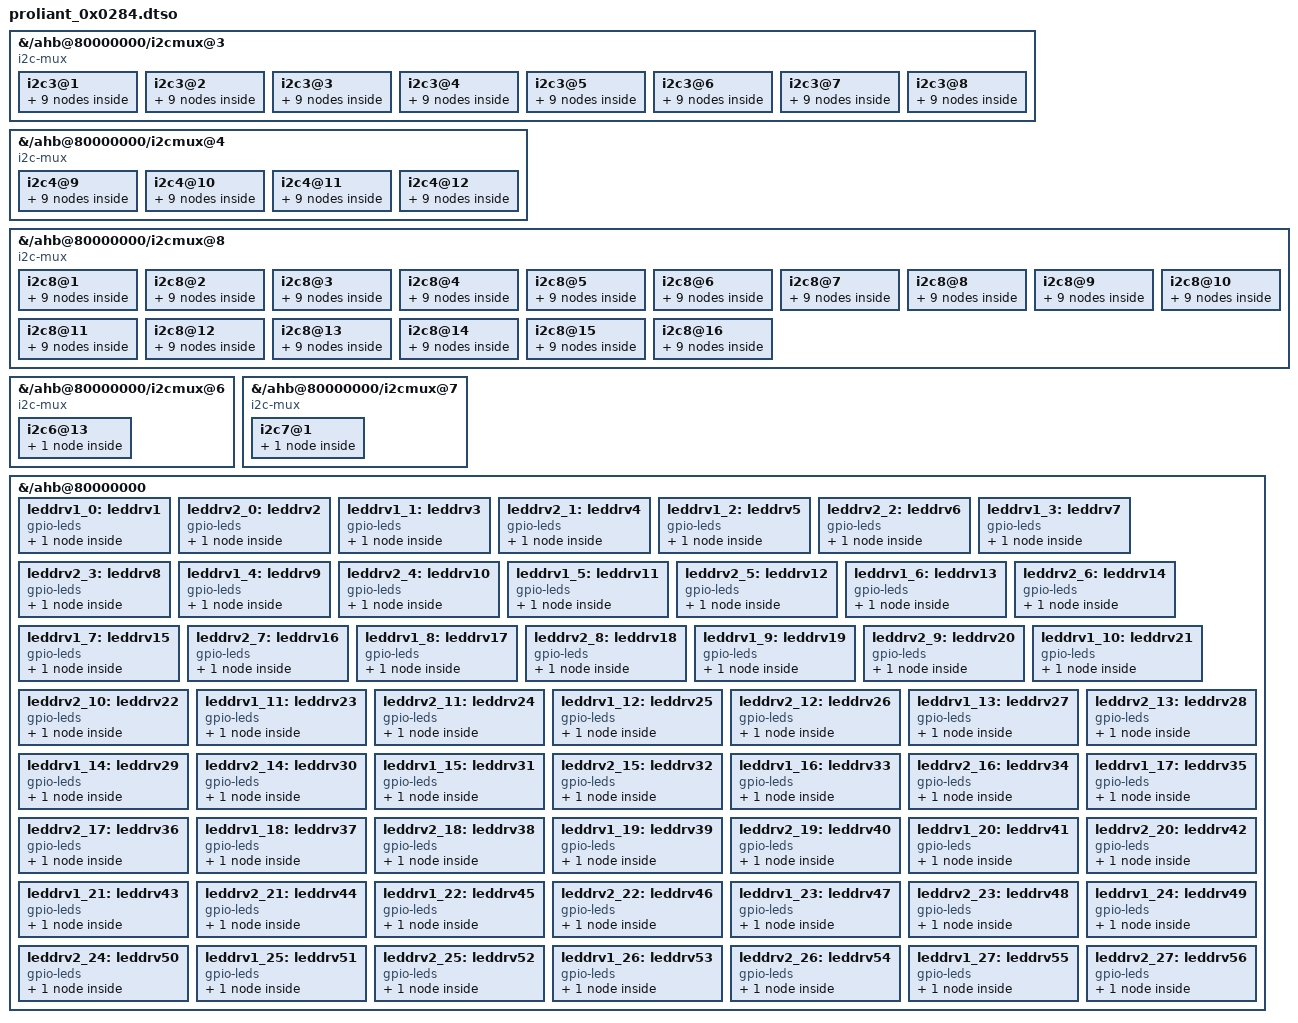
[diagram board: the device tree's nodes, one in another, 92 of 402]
/dts-v1/;
/plugin/;
/*
 * Device Tree Source Overlay for HPE ProLiant platform 0x0284
 * Auto-generated by platdef_parser.py from BIOS platdef data.
 *
 * i2cmux@N = platdef Engine N  |  sel value = i2cN@sel in child node
 *
 * i2cmux@3 (CPLD 0x87): 8 UBM channel(s), sel 1-8
 * i2cmux@4 (CPLD 0x88): 4 UBM channel(s), sel 9-12
 * i2cmux@8 (CPLD 0x8c): 16 UBM channel(s), sel 1-16
 * i2cmux@6: Power Supply 2 (psu2) sel=13 addr=0x5c
 * i2cmux@7: Power Supply 1 (psu1) sel=1 addr=0x5c
 */

/ {
	/*
	 * fragment@0: Engine 3 / i2cmux@3
	 * 8 UBM channel(s), sel 1-8
	 */
	fragment@0 {
		target-path = "/ahb@80000000/i2cmux@3";
		__overlay__ {

			/* sel=1  NVMe  (PCA9546 switch) */
			i2c3@1 {
				piceeprom0: piceeprom0 {
					compatible = "atmel,24c02";
					label = "piceeprom0";
					reg = <0x57>;
				};
				ubm0: ubm@40 {
					compatible = "ubm4";
					eeprom_phandle = <&piceeprom0>;
					reg = <0x40>;
					#gpio-cells = <2>;
					gpio-line-names = "0_DRV1_PRESENCE", "0_DRV1_UUID", "0_DRV1_ACT",
						"0_DRV2_PRESENCE", "0_DRV2_UUID", "0_DRV2_ACT";
				};
				switch@72 {
					compatible = "nxp,pca9546";
					#address-cells = <1>;
					#size-cells = <0>;
					reg = <0x72>;
					i2c@0 {
						#address-cells = <1>;
						#size-cells = <0>;
						reg = <0>;
						drveeprom@53 {
							compatible = "atmel,24c02";
							label = "drv1";
							reg = <0x53>;
						};
						thermsensor@1b {
							compatible = "ubm-drv";
							uid-led = <&leddrv1_0>;
							reg = <0x1b>;
						};
					};
					i2c@1 {
						#address-cells = <1>;
						#size-cells = <0>;
						reg = <1>;
						drveeprom@53 {
							compatible = "atmel,24c02";
							label = "drv2";
							reg = <0x53>;
						};
						thermsensor@1b {
							compatible = "ubm-drv";
							uid-led = <&leddrv2_0>;
							reg = <0x1b>;
						};
					};
				};
			}; /* i2c3@1 */

			/* sel=2  NVMe  (PCA9546 switch) */
			i2c3@2 {
				piceeprom1: piceeprom1 {
					compatible = "atmel,24c02";
					label = "piceeprom1";
					reg = <0x57>;
				};
				ubm1: ubm@40 {
					compatible = "ubm4";
					eeprom_phandle = <&piceeprom1>;
					reg = <0x40>;
					#gpio-cells = <2>;
					gpio-line-names = "0_DRV1_PRESENCE", "0_DRV1_UUID", "0_DRV1_ACT",
						"0_DRV2_PRESENCE", "0_DRV2_UUID", "0_DRV2_ACT";
				};
				switch@72 {
					compatible = "nxp,pca9546";
					#address-cells = <1>;
					#size-cells = <0>;
					reg = <0x72>;
					i2c@0 {
						#address-cells = <1>;
						#size-cells = <0>;
						reg = <0>;
						drveeprom@53 {
							compatible = "atmel,24c02";
							label = "drv3";
							reg = <0x53>;
						};
						thermsensor@1b {
							compatible = "ubm-drv";
							uid-led = <&leddrv1_1>;
							reg = <0x1b>;
						};
					};
					i2c@1 {
						#address-cells = <1>;
						#size-cells = <0>;
						reg = <1>;
						drveeprom@53 {
							compatible = "atmel,24c02";
							label = "drv4";
							reg = <0x53>;
						};
						thermsensor@1b {
							compatible = "ubm-drv";
							uid-led = <&leddrv2_1>;
							reg = <0x1b>;
						};
					};
				};
			}; /* i2c3@2 */

			/* sel=3  NVMe  (PCA9546 switch) */
			i2c3@3 {
				piceeprom2: piceeprom2 {
					compatible = "atmel,24c02";
					label = "piceeprom2";
					reg = <0x57>;
				};
				ubm2: ubm@40 {
					compatible = "ubm4";
					eeprom_phandle = <&piceeprom2>;
					reg = <0x40>;
					#gpio-cells = <2>;
					gpio-line-names = "0_DRV1_PRESENCE", "0_DRV1_UUID", "0_DRV1_ACT",
						"0_DRV2_PRESENCE", "0_DRV2_UUID", "0_DRV2_ACT";
				};
				switch@72 {
					compatible = "nxp,pca9546";
					#address-cells = <1>;
					#size-cells = <0>;
					reg = <0x72>;
					i2c@0 {
						#address-cells = <1>;
						#size-cells = <0>;
						reg = <0>;
						drveeprom@53 {
							compatible = "atmel,24c02";
							label = "drv5";
							reg = <0x53>;
						};
						thermsensor@1b {
							compatible = "ubm-drv";
							uid-led = <&leddrv1_2>;
							reg = <0x1b>;
						};
					};
					i2c@1 {
						#address-cells = <1>;
						#size-cells = <0>;
						reg = <1>;
						drveeprom@53 {
							compatible = "atmel,24c02";
							label = "drv6";
							reg = <0x53>;
						};
						thermsensor@1b {
							compatible = "ubm-drv";
							uid-led = <&leddrv2_2>;
							reg = <0x1b>;
						};
					};
				};
			}; /* i2c3@3 */

			/* sel=4  NVMe  (PCA9546 switch) */
			i2c3@4 {
				piceeprom3: piceeprom3 {
					compatible = "atmel,24c02";
					label = "piceeprom3";
					reg = <0x57>;
				};
				ubm3: ubm@40 {
					compatible = "ubm4";
					eeprom_phandle = <&piceeprom3>;
					reg = <0x40>;
					#gpio-cells = <2>;
					gpio-line-names = "0_DRV1_PRESENCE", "0_DRV1_UUID", "0_DRV1_ACT",
						"0_DRV2_PRESENCE", "0_DRV2_UUID", "0_DRV2_ACT";
				};
				switch@72 {
					compatible = "nxp,pca9546";
					#address-cells = <1>;
					#size-cells = <0>;
					reg = <0x72>;
					i2c@0 {
						#address-cells = <1>;
						#size-cells = <0>;
						reg = <0>;
						drveeprom@53 {
							compatible = "atmel,24c02";
							label = "drv7";
							reg = <0x53>;
						};
						thermsensor@1b {
							compatible = "ubm-drv";
							uid-led = <&leddrv1_3>;
							reg = <0x1b>;
						};
					};
					i2c@1 {
						#address-cells = <1>;
						#size-cells = <0>;
						reg = <1>;
						drveeprom@53 {
							compatible = "atmel,24c02";
							label = "drv8";
							reg = <0x53>;
						};
						thermsensor@1b {
							compatible = "ubm-drv";
							uid-led = <&leddrv2_3>;
							reg = <0x1b>;
						};
					};
				};
			}; /* i2c3@4 */

			/* sel=5  NVMe  (PCA9546 switch) */
			i2c3@5 {
				piceeprom4: piceeprom4 {
					compatible = "atmel,24c02";
					label = "piceeprom4";
					reg = <0x57>;
				};
				ubm4: ubm@40 {
					compatible = "ubm4";
					eeprom_phandle = <&piceeprom4>;
					reg = <0x40>;
					#gpio-cells = <2>;
					gpio-line-names = "0_DRV1_PRESENCE", "0_DRV1_UUID", "0_DRV1_ACT",
						"0_DRV2_PRESENCE", "0_DRV2_UUID", "0_DRV2_ACT";
				};
				switch@72 {
					compatible = "nxp,pca9546";
					#address-cells = <1>;
					#size-cells = <0>;
					reg = <0x72>;
					i2c@0 {
						#address-cells = <1>;
						#size-cells = <0>;
						reg = <0>;
						drveeprom@53 {
							compatible = "atmel,24c02";
							label = "drv9";
							reg = <0x53>;
						};
						thermsensor@1b {
							compatible = "ubm-drv";
							uid-led = <&leddrv1_4>;
							reg = <0x1b>;
						};
					};
					i2c@1 {
						#address-cells = <1>;
						#size-cells = <0>;
						reg = <1>;
						drveeprom@53 {
							compatible = "atmel,24c02";
							label = "drv10";
							reg = <0x53>;
						};
						thermsensor@1b {
							compatible = "ubm-drv";
							uid-led = <&leddrv2_4>;
							reg = <0x1b>;
						};
					};
				};
			}; /* i2c3@5 */

			/* sel=6  NVMe  (PCA9546 switch) */
			i2c3@6 {
				piceeprom5: piceeprom5 {
					compatible = "atmel,24c02";
					label = "piceeprom5";
					reg = <0x57>;
				};
				ubm5: ubm@40 {
					compatible = "ubm4";
					eeprom_phandle = <&piceeprom5>;
					reg = <0x40>;
					#gpio-cells = <2>;
					gpio-line-names = "0_DRV1_PRESENCE", "0_DRV1_UUID", "0_DRV1_ACT",
						"0_DRV2_PRESENCE", "0_DRV2_UUID", "0_DRV2_ACT";
				};
				switch@72 {
					compatible = "nxp,pca9546";
					#address-cells = <1>;
					#size-cells = <0>;
					reg = <0x72>;
					i2c@0 {
						#address-cells = <1>;
						#size-cells = <0>;
						reg = <0>;
						drveeprom@53 {
							compatible = "atmel,24c02";
							label = "drv11";
							reg = <0x53>;
						};
						thermsensor@1b {
							compatible = "ubm-drv";
							uid-led = <&leddrv1_5>;
							reg = <0x1b>;
						};
					};
					i2c@1 {
						#address-cells = <1>;
						#size-cells = <0>;
						reg = <1>;
						drveeprom@53 {
							compatible = "atmel,24c02";
							label = "drv12";
							reg = <0x53>;
						};
						thermsensor@1b {
							compatible = "ubm-drv";
							uid-led = <&leddrv2_5>;
							reg = <0x1b>;
						};
					};
				};
			}; /* i2c3@6 */

			/* sel=7  NVMe  (PCA9546 switch) */
			i2c3@7 {
				piceeprom6: piceeprom6 {
					compatible = "atmel,24c02";
					label = "piceeprom6";
					reg = <0x57>;
				};
				ubm6: ubm@40 {
					compatible = "ubm4";
					eeprom_phandle = <&piceeprom6>;
					reg = <0x40>;
					#gpio-cells = <2>;
					gpio-line-names = "0_DRV1_PRESENCE", "0_DRV1_UUID", "0_DRV1_ACT",
						"0_DRV2_PRESENCE", "0_DRV2_UUID", "0_DRV2_ACT";
				};
				switch@72 {
					compatible = "nxp,pca9546";
					#address-cells = <1>;
					#size-cells = <0>;
					reg = <0x72>;
					i2c@0 {
						#address-cells = <1>;
						#size-cells = <0>;
						reg = <0>;
						drveeprom@53 {
							compatible = "atmel,24c02";
							label = "drv13";
							reg = <0x53>;
						};
						thermsensor@1b {
							compatible = "ubm-drv";
							uid-led = <&leddrv1_6>;
							reg = <0x1b>;
						};
					};
					i2c@1 {
						#address-cells = <1>;
						#size-cells = <0>;
						reg = <1>;
						drveeprom@53 {
							compatible = "atmel,24c02";
							label = "drv14";
							reg = <0x53>;
						};
						thermsensor@1b {
							compatible = "ubm-drv";
							uid-led = <&leddrv2_6>;
							reg = <0x1b>;
						};
					};
				};
			}; /* i2c3@7 */

			/* sel=8  NVMe  (PCA9546 switch) */
			i2c3@8 {
				piceeprom7: piceeprom7 {
					compatible = "atmel,24c02";
					label = "piceeprom7";
					reg = <0x57>;
				};
				ubm7: ubm@40 {
					compatible = "ubm4";
					eeprom_phandle = <&piceeprom7>;
					reg = <0x40>;
					#gpio-cells = <2>;
					gpio-line-names = "0_DRV1_PRESENCE", "0_DRV1_UUID", "0_DRV1_ACT",
						"0_DRV2_PRESENCE", "0_DRV2_UUID", "0_DRV2_ACT";
				};
				switch@72 {
					compatible = "nxp,pca9546";
					#address-cells = <1>;
					#size-cells = <0>;
					reg = <0x72>;
					i2c@0 {
						#address-cells = <1>;
						#size-cells = <0>;
						reg = <0>;
						drveeprom@53 {
							compatible = "atmel,24c02";
							label = "drv15";
							reg = <0x53>;
						};
						thermsensor@1b {
							compatible = "ubm-drv";
							uid-led = <&leddrv1_7>;
							reg = <0x1b>;
						};
					};
					i2c@1 {
						#address-cells = <1>;
						#size-cells = <0>;
						reg = <1>;
						drveeprom@53 {
							compatible = "atmel,24c02";
							label = "drv16";
							reg = <0x53>;
						};
						thermsensor@1b {
							compatible = "ubm-drv";
							uid-led = <&leddrv2_7>;
							reg = <0x1b>;
						};
					};
				};
			}; /* i2c3@8 */

		}; /* __overlay__ */
	}; /* fragment@0 */

	/*
	 * fragment@1: Engine 4 / i2cmux@4
	 * 4 UBM channel(s), sel 9-12
	 */
	fragment@1 {
		target-path = "/ahb@80000000/i2cmux@4";
		__overlay__ {

			/* sel=9  NVMe  (PCA9546 switch) */
			i2c4@9 {
				piceeprom8: piceeprom8 {
					compatible = "atmel,24c02";
					label = "piceeprom8";
					reg = <0x57>;
				};
				ubm8: ubm@40 {
					compatible = "ubm4";
					eeprom_phandle = <&piceeprom8>;
					reg = <0x40>;
					#gpio-cells = <2>;
					gpio-line-names = "0_DRV1_PRESENCE", "0_DRV1_UUID", "0_DRV1_ACT",
						"0_DRV2_PRESENCE", "0_DRV2_UUID", "0_DRV2_ACT";
				};
				switch@72 {
					compatible = "nxp,pca9546";
					#address-cells = <1>;
					#size-cells = <0>;
					reg = <0x72>;
					i2c@0 {
						#address-cells = <1>;
						#size-cells = <0>;
						reg = <0>;
						drveeprom@53 {
							compatible = "atmel,24c02";
							label = "drv17";
							reg = <0x53>;
						};
						thermsensor@1b {
							compatible = "ubm-drv";
							uid-led = <&leddrv1_8>;
							reg = <0x1b>;
						};
					};
					i2c@1 {
						#address-cells = <1>;
						#size-cells = <0>;
						reg = <1>;
						drveeprom@53 {
							compatible = "atmel,24c02";
							label = "drv18";
							reg = <0x53>;
						};
						thermsensor@1b {
							compatible = "ubm-drv";
							uid-led = <&leddrv2_8>;
							reg = <0x1b>;
						};
					};
				};
			}; /* i2c4@9 */

			/* sel=10  NVMe  (PCA9546 switch) */
			i2c4@10 {
				piceeprom9: piceeprom9 {
					compatible = "atmel,24c02";
					label = "piceeprom9";
					reg = <0x57>;
				};
				ubm9: ubm@40 {
					compatible = "ubm4";
					eeprom_phandle = <&piceeprom9>;
					reg = <0x40>;
					#gpio-cells = <2>;
					gpio-line-names = "0_DRV1_PRESENCE", "0_DRV1_UUID", "0_DRV1_ACT",
						"0_DRV2_PRESENCE", "0_DRV2_UUID", "0_DRV2_ACT";
				};
				switch@72 {
					compatible = "nxp,pca9546";
					#address-cells = <1>;
					#size-cells = <0>;
					reg = <0x72>;
					i2c@0 {
						#address-cells = <1>;
						#size-cells = <0>;
						reg = <0>;
						drveeprom@53 {
							compatible = "atmel,24c02";
							label = "drv19";
							reg = <0x53>;
						};
						thermsensor@1b {
							compatible = "ubm-drv";
							uid-led = <&leddrv1_9>;
							reg = <0x1b>;
						};
					};
					i2c@1 {
						#address-cells = <1>;
						#size-cells = <0>;
						reg = <1>;
						drveeprom@53 {
							compatible = "atmel,24c02";
							label = "drv20";
							reg = <0x53>;
						};
						thermsensor@1b {
							compatible = "ubm-drv";
							uid-led = <&leddrv2_9>;
							reg = <0x1b>;
						};
					};
				};
			}; /* i2c4@10 */

			/* sel=11  NVMe  (PCA9546 switch) */
			i2c4@11 {
				piceeprom10: piceeprom10 {
					compatible = "atmel,24c02";
					label = "piceeprom10";
					reg = <0x57>;
				};
				ubm10: ubm@40 {
					compatible = "ubm4";
					eeprom_phandle = <&piceeprom10>;
					reg = <0x40>;
					#gpio-cells = <2>;
					gpio-line-names = "0_DRV1_PRESENCE", "0_DRV1_UUID", "0_DRV1_ACT",
						"0_DRV2_PRESENCE", "0_DRV2_UUID", "0_DRV2_ACT";
				};
				switch@72 {
					compatible = "nxp,pca9546";
					#address-cells = <1>;
					#size-cells = <0>;
					reg = <0x72>;
					i2c@0 {
						#address-cells = <1>;
						#size-cells = <0>;
						reg = <0>;
						drveeprom@53 {
							compatible = "atmel,24c02";
							label = "drv21";
							reg = <0x53>;
						};
						thermsensor@1b {
							compatible = "ubm-drv";
							uid-led = <&leddrv1_10>;
							reg = <0x1b>;
						};
					};
					i2c@1 {
						#address-cells = <1>;
						#size-cells = <0>;
						reg = <1>;
						drveeprom@53 {
							compatible = "atmel,24c02";
							label = "drv22";
							reg = <0x53>;
						};
						thermsensor@1b {
							compatible = "ubm-drv";
							uid-led = <&leddrv2_10>;
							reg = <0x1b>;
						};
					};
				};
			}; /* i2c4@11 */

			/* sel=12  NVMe  (PCA9546 switch) */
			i2c4@12 {
				piceeprom11: piceeprom11 {
					compatible = "atmel,24c02";
					label = "piceeprom11";
					reg = <0x57>;
				};
				ubm11: ubm@40 {
					compatible = "ubm4";
					eeprom_phandle = <&piceeprom11>;
					reg = <0x40>;
					#gpio-cells = <2>;
					gpio-line-names = "0_DRV1_PRESENCE", "0_DRV1_UUID", "0_DRV1_ACT",
						"0_DRV2_PRESENCE", "0_DRV2_UUID", "0_DRV2_ACT";
				};
				switch@72 {
					compatible = "nxp,pca9546";
					#address-cells = <1>;
					#size-cells = <0>;
					reg = <0x72>;
					i2c@0 {
						#address-cells = <1>;
						#size-cells = <0>;
						reg = <0>;
						drveeprom@53 {
							compatible = "atmel,24c02";
							label = "drv23";
							reg = <0x53>;
						};
						thermsensor@1b {
							compatible = "ubm-drv";
							uid-led = <&leddrv1_11>;
							reg = <0x1b>;
						};
					};
					i2c@1 {
						#address-cells = <1>;
						#size-cells = <0>;
						reg = <1>;
						drveeprom@53 {
							compatible = "atmel,24c02";
							label = "drv24";
							reg = <0x53>;
						};
						thermsensor@1b {
							compatible = "ubm-drv";
							uid-led = <&leddrv2_11>;
							reg = <0x1b>;
						};
					};
				};
			}; /* i2c4@12 */

		}; /* __overlay__ */
	}; /* fragment@1 */

	/*
	 * fragment@2: Engine 8 / i2cmux@8
	 * 16 UBM channel(s), sel 1-16
	 */
	fragment@2 {
		target-path = "/ahb@80000000/i2cmux@8";
		__overlay__ {

			/* sel=1  NVMe  (PCA9546 switch) */
			i2c8@1 {
				piceeprom12: piceeprom12 {
					compatible = "atmel,24c02";
					label = "piceeprom12";
					reg = <0x57>;
				};
				ubm12: ubm@40 {
					compatible = "ubm4";
					eeprom_phandle = <&piceeprom12>;
					reg = <0x40>;
					#gpio-cells = <2>;
					gpio-line-names = "0_DRV1_PRESENCE", "0_DRV1_UUID", "0_DRV1_ACT",
						"0_DRV2_PRESENCE", "0_DRV2_UUID", "0_DRV2_ACT";
				};
				switch@72 {
					compatible = "nxp,pca9546";
					#address-cells = <1>;
					#size-cells = <0>;
					reg = <0x72>;
					i2c@0 {
						#address-cells = <1>;
						#size-cells = <0>;
						reg = <0>;
						drveeprom@53 {
							compatible = "atmel,24c02";
							label = "drv25";
							reg = <0x53>;
						};
						thermsensor@1b {
							compatible = "ubm-drv";
							uid-led = <&leddrv1_12>;
							reg = <0x1b>;
						};
					};
					i2c@1 {
						#address-cells = <1>;
						#size-cells = <0>;
						reg = <1>;
						drveeprom@53 {
							compatible = "atmel,24c02";
							label = "drv26";
							reg = <0x53>;
						};
						thermsensor@1b {
							compatible = "ubm-drv";
							uid-led = <&leddrv2_12>;
							reg = <0x1b>;
						};
					};
				};
			}; /* i2c8@1 */

			/* sel=2  NVMe  (PCA9546 switch) */
			i2c8@2 {
				piceeprom13: piceeprom13 {
					compatible = "atmel,24c02";
					label = "piceeprom13";
					reg = <0x57>;
				};
				ubm13: ubm@40 {
					compatible = "ubm4";
					eeprom_phandle = <&piceeprom13>;
					reg = <0x40>;
					#gpio-cells = <2>;
					gpio-line-names = "0_DRV1_PRESENCE", "0_DRV1_UUID", "0_DRV1_ACT",
						"0_DRV2_PRESENCE", "0_DRV2_UUID", "0_DRV2_ACT";
				};
				switch@72 {
					compatible = "nxp,pca9546";
					#address-cells = <1>;
					#size-cells = <0>;
					reg = <0x72>;
					i2c@0 {
						#address-cells = <1>;
						#size-cells = <0>;
						reg = <0>;
						drveeprom@53 {
							compatible = "atmel,24c02";
							label = "drv27";
							reg = <0x53>;
						};
						thermsensor@1b {
							compatible = "ubm-drv";
							uid-led = <&leddrv1_13>;
							reg = <0x1b>;
						};
					};
					i2c@1 {
						#address-cells = <1>;
						#size-cells = <0>;
						reg = <1>;
						drveeprom@53 {
							compatible = "atmel,24c02";
							label = "drv28";
							reg = <0x53>;
						};
						thermsensor@1b {
							compatible = "ubm-drv";
							uid-led = <&leddrv2_13>;
							reg = <0x1b>;
						};
					};
				};
			}; /* i2c8@2 */

			/* sel=3  NVMe  (PCA9546 switch) */
			i2c8@3 {
				piceeprom14: piceeprom14 {
					compatible = "atmel,24c02";
					label = "piceeprom14";
					reg = <0x57>;
				};
				ubm14: ubm@40 {
					compatible = "ubm4";
					eeprom_phandle = <&piceeprom14>;
					reg = <0x40>;
					#gpio-cells = <2>;
					gpio-line-names = "0_DRV1_PRESENCE", "0_DRV1_UUID", "0_DRV1_ACT",
						"0_DRV2_PRESENCE", "0_DRV2_UUID", "0_DRV2_ACT";
				};
				switch@72 {
					compatible = "nxp,pca9546";
					#address-cells = <1>;
					#size-cells = <0>;
					reg = <0x72>;
					i2c@0 {
						#address-cells = <1>;
						#size-cells = <0>;
						reg = <0>;
						drveeprom@53 {
							compatible = "atmel,24c02";
							label = "drv29";
							reg = <0x53>;
						};
						thermsensor@1b {
							compatible = "ubm-drv";
							uid-led = <&leddrv1_14>;
							reg = <0x1b>;
						};
					};
					i2c@1 {
						#address-cells = <1>;
						#size-cells = <0>;
						reg = <1>;
						drveeprom@53 {
							compatible = "atmel,24c02";
							label = "drv30";
							reg = <0x53>;
						};
						thermsensor@1b {
							compatible = "ubm-drv";
							uid-led = <&leddrv2_14>;
							reg = <0x1b>;
						};
					};
				};
			}; /* i2c8@3 */

			/* sel=4  NVMe  (PCA9546 switch) */
			i2c8@4 {
				piceeprom15: piceeprom15 {
					compatible = "atmel,24c02";
					label = "piceeprom15";
					reg = <0x57>;
				};
				ubm15: ubm@40 {
					compatible = "ubm4";
					eeprom_phandle = <&piceeprom15>;
					reg = <0x40>;
					#gpio-cells = <2>;
					gpio-line-names = "0_DRV1_PRESENCE", "0_DRV1_UUID", "0_DRV1_ACT",
						"0_DRV2_PRESENCE", "0_DRV2_UUID", "0_DRV2_ACT";
				};
				switch@72 {
					compatible = "nxp,pca9546";
					#address-cells = <1>;
					#size-cells = <0>;
					reg = <0x72>;
					i2c@0 {
						#address-cells = <1>;
						#size-cells = <0>;
						reg = <0>;
						drveeprom@53 {
							compatible = "atmel,24c02";
							label = "drv31";
							reg = <0x53>;
						};
						thermsensor@1b {
							compatible = "ubm-drv";
							uid-led = <&leddrv1_15>;
							reg = <0x1b>;
						};
					};
					i2c@1 {
						#address-cells = <1>;
						#size-cells = <0>;
						reg = <1>;
						drveeprom@53 {
							compatible = "atmel,24c02";
							label = "drv32";
							reg = <0x53>;
						};
						thermsensor@1b {
							compatible = "ubm-drv";
							uid-led = <&leddrv2_15>;
							reg = <0x1b>;
						};
					};
				};
			}; /* i2c8@4 */

			/* sel=5  NVMe  (PCA9546 switch) */
			i2c8@5 {
				piceeprom16: piceeprom16 {
					compatible = "atmel,24c02";
					label = "piceeprom16";
					reg = <0x57>;
				};
				ubm16: ubm@40 {
					compatible = "ubm4";
					eeprom_phandle = <&piceeprom16>;
					reg = <0x40>;
					#gpio-cells = <2>;
					gpio-line-names = "0_DRV1_PRESENCE", "0_DRV1_UUID", "0_DRV1_ACT",
						"0_DRV2_PRESENCE", "0_DRV2_UUID", "0_DRV2_ACT";
				};
				switch@72 {
					compatible = "nxp,pca9546";
					#address-cells = <1>;
					#size-cells = <0>;
					reg = <0x72>;
					i2c@0 {
						#address-cells = <1>;
						#size-cells = <0>;
						reg = <0>;
						drveeprom@53 {
							compatible = "atmel,24c02";
							label = "drv33";
							reg = <0x53>;
						};
						thermsensor@1b {
							compatible = "ubm-drv";
							uid-led = <&leddrv1_16>;
							reg = <0x1b>;
						};
					};
					i2c@1 {
						#address-cells = <1>;
						#size-cells = <0>;
						reg = <1>;
						drveeprom@53 {
							compatible = "atmel,24c02";
							label = "drv34";
							reg = <0x53>;
						};
						thermsensor@1b {
							compatible = "ubm-drv";
							uid-led = <&leddrv2_16>;
							reg = <0x1b>;
						};
					};
				};
			}; /* i2c8@5 */

			/* sel=6  NVMe  (PCA9546 switch) */
			i2c8@6 {
				piceeprom17: piceeprom17 {
					compatible = "atmel,24c02";
					label = "piceeprom17";
					reg = <0x57>;
				};
				ubm17: ubm@40 {
					compatible = "ubm4";
					eeprom_phandle = <&piceeprom17>;
					reg = <0x40>;
					#gpio-cells = <2>;
					gpio-line-names = "0_DRV1_PRESENCE", "0_DRV1_UUID", "0_DRV1_ACT",
						"0_DRV2_PRESENCE", "0_DRV2_UUID", "0_DRV2_ACT";
				};
				switch@72 {
					compatible = "nxp,pca9546";
					#address-cells = <1>;
					#size-cells = <0>;
					reg = <0x72>;
					i2c@0 {
						#address-cells = <1>;
						#size-cells = <0>;
						reg = <0>;
						drveeprom@53 {
							compatible = "atmel,24c02";
							label = "drv35";
							reg = <0x53>;
						};
						thermsensor@1b {
							compatible = "ubm-drv";
							uid-led = <&leddrv1_17>;
							reg = <0x1b>;
						};
					};
					i2c@1 {
						#address-cells = <1>;
						#size-cells = <0>;
						reg = <1>;
						drveeprom@53 {
							compatible = "atmel,24c02";
							label = "drv36";
							reg = <0x53>;
						};
						thermsensor@1b {
							compatible = "ubm-drv";
							uid-led = <&leddrv2_17>;
							reg = <0x1b>;
						};
					};
				};
			}; /* i2c8@6 */

			/* sel=7  NVMe  (PCA9546 switch) */
			i2c8@7 {
				piceeprom18: piceeprom18 {
					compatible = "atmel,24c02";
					label = "piceeprom18";
					reg = <0x57>;
				};
				ubm18: ubm@40 {
					compatible = "ubm4";
					eeprom_phandle = <&piceeprom18>;
					reg = <0x40>;
					#gpio-cells = <2>;
					gpio-line-names = "0_DRV1_PRESENCE", "0_DRV1_UUID", "0_DRV1_ACT",
						"0_DRV2_PRESENCE", "0_DRV2_UUID", "0_DRV2_ACT";
				};
				switch@72 {
					compatible = "nxp,pca9546";
					#address-cells = <1>;
					#size-cells = <0>;
					reg = <0x72>;
					i2c@0 {
						#address-cells = <1>;
						#size-cells = <0>;
						reg = <0>;
						drveeprom@53 {
							compatible = "atmel,24c02";
							label = "drv37";
							reg = <0x53>;
						};
						thermsensor@1b {
							compatible = "ubm-drv";
							uid-led = <&leddrv1_18>;
							reg = <0x1b>;
						};
					};
					i2c@1 {
						#address-cells = <1>;
						#size-cells = <0>;
						reg = <1>;
						drveeprom@53 {
							compatible = "atmel,24c02";
							label = "drv38";
							reg = <0x53>;
						};
						thermsensor@1b {
							compatible = "ubm-drv";
							uid-led = <&leddrv2_18>;
							reg = <0x1b>;
						};
					};
				};
			}; /* i2c8@7 */

			/* sel=8  NVMe  (PCA9546 switch) */
			i2c8@8 {
				piceeprom19: piceeprom19 {
					compatible = "atmel,24c02";
					label = "piceeprom19";
					reg = <0x57>;
				};
				ubm19: ubm@40 {
					compatible = "ubm4";
					eeprom_phandle = <&piceeprom19>;
					reg = <0x40>;
					#gpio-cells = <2>;
					gpio-line-names = "0_DRV1_PRESENCE", "0_DRV1_UUID", "0_DRV1_ACT",
						"0_DRV2_PRESENCE", "0_DRV2_UUID", "0_DRV2_ACT";
				};
				switch@72 {
					compatible = "nxp,pca9546";
					#address-cells = <1>;
					#size-cells = <0>;
					reg = <0x72>;
					i2c@0 {
						#address-cells = <1>;
						#size-cells = <0>;
						reg = <0>;
						drveeprom@53 {
							compatible = "atmel,24c02";
							label = "drv39";
							reg = <0x53>;
						};
						thermsensor@1b {
							compatible = "ubm-drv";
							uid-led = <&leddrv1_19>;
							reg = <0x1b>;
						};
					};
					i2c@1 {
						#address-cells = <1>;
						#size-cells = <0>;
						reg = <1>;
						drveeprom@53 {
							compatible = "atmel,24c02";
							label = "drv40";
							reg = <0x53>;
						};
						thermsensor@1b {
							compatible = "ubm-drv";
							uid-led = <&leddrv2_19>;
							reg = <0x1b>;
						};
					};
				};
			}; /* i2c8@8 */

			/* sel=9  NVMe  (PCA9546 switch) */
			i2c8@9 {
				piceeprom20: piceeprom20 {
					compatible = "atmel,24c02";
					label = "piceeprom20";
					reg = <0x57>;
				};
				ubm20: ubm@40 {
					compatible = "ubm4";
					eeprom_phandle = <&piceeprom20>;
					reg = <0x40>;
					#gpio-cells = <2>;
					gpio-line-names = "0_DRV1_PRESENCE", "0_DRV1_UUID", "0_DRV1_ACT",
						"0_DRV2_PRESENCE", "0_DRV2_UUID", "0_DRV2_ACT";
				};
				switch@72 {
					compatible = "nxp,pca9546";
					#address-cells = <1>;
					#size-cells = <0>;
					reg = <0x72>;
					i2c@0 {
						#address-cells = <1>;
						#size-cells = <0>;
						reg = <0>;
						drveeprom@53 {
							compatible = "atmel,24c02";
							label = "drv41";
							reg = <0x53>;
						};
						thermsensor@1b {
							compatible = "ubm-drv";
							uid-led = <&leddrv1_20>;
							reg = <0x1b>;
						};
					};
					i2c@1 {
						#address-cells = <1>;
						#size-cells = <0>;
						reg = <1>;
						drveeprom@53 {
							compatible = "atmel,24c02";
							label = "drv42";
							reg = <0x53>;
						};
						thermsensor@1b {
							compatible = "ubm-drv";
							uid-led = <&leddrv2_20>;
							reg = <0x1b>;
						};
					};
				};
			}; /* i2c8@9 */

			/* sel=10  NVMe  (PCA9546 switch) */
			i2c8@10 {
				piceeprom21: piceeprom21 {
					compatible = "atmel,24c02";
					label = "piceeprom21";
					reg = <0x57>;
				};
				ubm21: ubm@40 {
					compatible = "ubm4";
					eeprom_phandle = <&piceeprom21>;
					reg = <0x40>;
					#gpio-cells = <2>;
					gpio-line-names = "0_DRV1_PRESENCE", "0_DRV1_UUID", "0_DRV1_ACT",
						"0_DRV2_PRESENCE", "0_DRV2_UUID", "0_DRV2_ACT";
				};
				switch@72 {
					compatible = "nxp,pca9546";
					#address-cells = <1>;
					#size-cells = <0>;
					reg = <0x72>;
					i2c@0 {
						#address-cells = <1>;
						#size-cells = <0>;
						reg = <0>;
						drveeprom@53 {
							compatible = "atmel,24c02";
							label = "drv43";
							reg = <0x53>;
						};
						thermsensor@1b {
							compatible = "ubm-drv";
							uid-led = <&leddrv1_21>;
							reg = <0x1b>;
						};
					};
					i2c@1 {
						#address-cells = <1>;
						#size-cells = <0>;
						reg = <1>;
						drveeprom@53 {
							compatible = "atmel,24c02";
							label = "drv44";
							reg = <0x53>;
						};
						thermsensor@1b {
							compatible = "ubm-drv";
							uid-led = <&leddrv2_21>;
							reg = <0x1b>;
						};
					};
				};
			}; /* i2c8@10 */

			/* sel=11  NVMe  (PCA9546 switch) */
			i2c8@11 {
				piceeprom22: piceeprom22 {
					compatible = "atmel,24c02";
					label = "piceeprom22";
					reg = <0x57>;
				};
				ubm22: ubm@40 {
					compatible = "ubm4";
					eeprom_phandle = <&piceeprom22>;
					reg = <0x40>;
					#gpio-cells = <2>;
					gpio-line-names = "0_DRV1_PRESENCE", "0_DRV1_UUID", "0_DRV1_ACT",
						"0_DRV2_PRESENCE", "0_DRV2_UUID", "0_DRV2_ACT";
				};
				switch@72 {
					compatible = "nxp,pca9546";
					#address-cells = <1>;
					#size-cells = <0>;
					reg = <0x72>;
					i2c@0 {
						#address-cells = <1>;
						#size-cells = <0>;
						reg = <0>;
						drveeprom@53 {
							compatible = "atmel,24c02";
							label = "drv45";
							reg = <0x53>;
						};
						thermsensor@1b {
							compatible = "ubm-drv";
							uid-led = <&leddrv1_22>;
							reg = <0x1b>;
						};
					};
					i2c@1 {
						#address-cells = <1>;
						#size-cells = <0>;
						reg = <1>;
						drveeprom@53 {
							compatible = "atmel,24c02";
							label = "drv46";
							reg = <0x53>;
						};
						thermsensor@1b {
							compatible = "ubm-drv";
							uid-led = <&leddrv2_22>;
							reg = <0x1b>;
						};
					};
				};
			}; /* i2c8@11 */

			/* sel=12  NVMe  (PCA9546 switch) */
			i2c8@12 {
				piceeprom23: piceeprom23 {
					compatible = "atmel,24c02";
					label = "piceeprom23";
					reg = <0x57>;
				};
				ubm23: ubm@40 {
					compatible = "ubm4";
					eeprom_phandle = <&piceeprom23>;
					reg = <0x40>;
					#gpio-cells = <2>;
					gpio-line-names = "0_DRV1_PRESENCE", "0_DRV1_UUID", "0_DRV1_ACT",
						"0_DRV2_PRESENCE", "0_DRV2_UUID", "0_DRV2_ACT";
				};
				switch@72 {
					compatible = "nxp,pca9546";
					#address-cells = <1>;
					#size-cells = <0>;
					reg = <0x72>;
					i2c@0 {
						#address-cells = <1>;
						#size-cells = <0>;
						reg = <0>;
						drveeprom@53 {
							compatible = "atmel,24c02";
							label = "drv47";
							reg = <0x53>;
						};
						thermsensor@1b {
							compatible = "ubm-drv";
							uid-led = <&leddrv1_23>;
							reg = <0x1b>;
						};
					};
					i2c@1 {
						#address-cells = <1>;
						#size-cells = <0>;
						reg = <1>;
						drveeprom@53 {
							compatible = "atmel,24c02";
							label = "drv48";
							reg = <0x53>;
						};
						thermsensor@1b {
							compatible = "ubm-drv";
							uid-led = <&leddrv2_23>;
							reg = <0x1b>;
						};
					};
				};
			}; /* i2c8@12 */

			/* sel=13  NVMe+SATA  (PCA9546 switch) */
			i2c8@13 {
				piceeprom24: piceeprom24 {
					compatible = "atmel,24c02";
					label = "piceeprom24";
					reg = <0x57>;
				};
				ubm24: ubm@40 {
					compatible = "ubm4";
					eeprom_phandle = <&piceeprom24>;
					reg = <0x40>;
					#gpio-cells = <2>;
					gpio-line-names = "0_DRV1_PRESENCE", "0_DRV1_UUID", "0_DRV1_ACT",
						"0_DRV2_PRESENCE", "0_DRV2_UUID", "0_DRV2_ACT";
				};
				switch@72 {
					compatible = "nxp,pca9546";
					#address-cells = <1>;
					#size-cells = <0>;
					reg = <0x72>;
					i2c@0 {
						#address-cells = <1>;
						#size-cells = <0>;
						reg = <0>;
						drveeprom@53 {
							compatible = "atmel,24c02";
							label = "drv49";
							reg = <0x53>;
						};
						thermsensor@1b {
							compatible = "ubm-drv";
							uid-led = <&leddrv1_24>;
							reg = <0x1b>;
						};
					};
					i2c@1 {
						#address-cells = <1>;
						#size-cells = <0>;
						reg = <1>;
						drveeprom@53 {
							compatible = "atmel,24c02";
							label = "drv50";
							reg = <0x53>;
						};
						thermsensor@1b {
							compatible = "ubm-drv";
							uid-led = <&leddrv2_24>;
							reg = <0x1b>;
						};
					};
				};
			}; /* i2c8@13 */

			/* sel=14  NVMe+SATA  (PCA9546 switch) */
			i2c8@14 {
				piceeprom25: piceeprom25 {
					compatible = "atmel,24c02";
					label = "piceeprom25";
					reg = <0x57>;
				};
				ubm25: ubm@40 {
					compatible = "ubm4";
					eeprom_phandle = <&piceeprom25>;
					reg = <0x40>;
					#gpio-cells = <2>;
					gpio-line-names = "0_DRV1_PRESENCE", "0_DRV1_UUID", "0_DRV1_ACT",
						"0_DRV2_PRESENCE", "0_DRV2_UUID", "0_DRV2_ACT";
				};
				switch@72 {
					compatible = "nxp,pca9546";
					#address-cells = <1>;
					#size-cells = <0>;
					reg = <0x72>;
					i2c@0 {
						#address-cells = <1>;
						#size-cells = <0>;
						reg = <0>;
						drveeprom@53 {
							compatible = "atmel,24c02";
							label = "drv51";
							reg = <0x53>;
						};
						thermsensor@1b {
							compatible = "ubm-drv";
							uid-led = <&leddrv1_25>;
							reg = <0x1b>;
						};
					};
					i2c@1 {
						#address-cells = <1>;
						#size-cells = <0>;
						reg = <1>;
						drveeprom@53 {
							compatible = "atmel,24c02";
							label = "drv52";
							reg = <0x53>;
						};
						thermsensor@1b {
							compatible = "ubm-drv";
							uid-led = <&leddrv2_25>;
							reg = <0x1b>;
						};
					};
				};
			}; /* i2c8@14 */

			/* sel=15  NVMe+SATA  (PCA9546 switch) */
			i2c8@15 {
				piceeprom26: piceeprom26 {
					compatible = "atmel,24c02";
					label = "piceeprom26";
					reg = <0x57>;
				};
				ubm26: ubm@40 {
					compatible = "ubm4";
					eeprom_phandle = <&piceeprom26>;
					reg = <0x40>;
					#gpio-cells = <2>;
					gpio-line-names = "0_DRV1_PRESENCE", "0_DRV1_UUID", "0_DRV1_ACT",
						"0_DRV2_PRESENCE", "0_DRV2_UUID", "0_DRV2_ACT";
				};
				switch@72 {
					compatible = "nxp,pca9546";
					#address-cells = <1>;
					#size-cells = <0>;
					reg = <0x72>;
					i2c@0 {
						#address-cells = <1>;
						#size-cells = <0>;
						reg = <0>;
						drveeprom@53 {
							compatible = "atmel,24c02";
							label = "drv53";
							reg = <0x53>;
						};
						thermsensor@1b {
							compatible = "ubm-drv";
							uid-led = <&leddrv1_26>;
							reg = <0x1b>;
						};
					};
					i2c@1 {
						#address-cells = <1>;
						#size-cells = <0>;
						reg = <1>;
						drveeprom@53 {
							compatible = "atmel,24c02";
							label = "drv54";
							reg = <0x53>;
						};
						thermsensor@1b {
							compatible = "ubm-drv";
							uid-led = <&leddrv2_26>;
							reg = <0x1b>;
						};
					};
				};
			}; /* i2c8@15 */

			/* sel=16  NVMe+SATA  (PCA9546 switch) */
			i2c8@16 {
				piceeprom27: piceeprom27 {
					compatible = "atmel,24c02";
					label = "piceeprom27";
					reg = <0x57>;
				};
				ubm27: ubm@40 {
					compatible = "ubm4";
					eeprom_phandle = <&piceeprom27>;
					reg = <0x40>;
					#gpio-cells = <2>;
					gpio-line-names = "0_DRV1_PRESENCE", "0_DRV1_UUID", "0_DRV1_ACT",
						"0_DRV2_PRESENCE", "0_DRV2_UUID", "0_DRV2_ACT";
				};
				switch@72 {
					compatible = "nxp,pca9546";
					#address-cells = <1>;
					#size-cells = <0>;
					reg = <0x72>;
					i2c@0 {
						#address-cells = <1>;
						#size-cells = <0>;
						reg = <0>;
						drveeprom@53 {
							compatible = "atmel,24c02";
							label = "drv55";
							reg = <0x53>;
						};
						thermsensor@1b {
							compatible = "ubm-drv";
							uid-led = <&leddrv1_27>;
							reg = <0x1b>;
						};
					};
					i2c@1 {
						#address-cells = <1>;
						#size-cells = <0>;
						reg = <1>;
						drveeprom@53 {
							compatible = "atmel,24c02";
							label = "drv56";
							reg = <0x53>;
						};
						thermsensor@1b {
							compatible = "ubm-drv";
							uid-led = <&leddrv2_27>;
							reg = <0x1b>;
						};
					};
				};
			}; /* i2c8@16 */

		}; /* __overlay__ */
	}; /* fragment@2 */

	/*
	 * fragment@3: Engine 6 / i2cmux@6 — PSU(s)
	 */
	fragment@3 {
		target-path = "/ahb@80000000/i2cmux@6";
		__overlay__ {

			/* Power Supply 2 */
			i2c6@13 {
				psu2: psu@5c {
					compatible = "hpe,crps185";
					reg = <0x5c>;
				};
			}; /* i2c6@13 */

		}; /* __overlay__ */
	}; /* fragment@3 */

	/*
	 * fragment@4: Engine 7 / i2cmux@7 — PSU(s)
	 */
	fragment@4 {
		target-path = "/ahb@80000000/i2cmux@7";
		__overlay__ {

			/* Power Supply 1 */
			i2c7@1 {
				psu1: psu@5c {
					compatible = "hpe,crps185";
					reg = <0x5c>;
				};
			}; /* i2c7@1 */

		}; /* __overlay__ */
	}; /* fragment@4 */

	/*
	 * fragment@5: LED GPIO drivers for all UBM bays
	 * gpio-leds nodes reference UBM chip GPIO outputs (pins 1 and 4).
	 * Verify pin assignments against platform schematic before production.
	 */
	fragment@5 {
		target-path = "/ahb@80000000";
		__overlay__ {

			leddrv1_0: leddrv1 {
				compatible = "gpio-leds";
				uid {
					gpios = <&ubm0 1 0>;
					default-state = "off";
				};
			};
			leddrv2_0: leddrv2 {
				compatible = "gpio-leds";
				uid {
					gpios = <&ubm0 4 0>;
					default-state = "off";
				};
			};
			leddrv1_1: leddrv3 {
				compatible = "gpio-leds";
				uid {
					gpios = <&ubm1 1 0>;
					default-state = "off";
				};
			};
			leddrv2_1: leddrv4 {
				compatible = "gpio-leds";
				uid {
					gpios = <&ubm1 4 0>;
					default-state = "off";
				};
			};
			leddrv1_2: leddrv5 {
				compatible = "gpio-leds";
				uid {
					gpios = <&ubm2 1 0>;
					default-state = "off";
				};
			};
			leddrv2_2: leddrv6 {
				compatible = "gpio-leds";
				uid {
					gpios = <&ubm2 4 0>;
					default-state = "off";
				};
			};
			leddrv1_3: leddrv7 {
				compatible = "gpio-leds";
				uid {
					gpios = <&ubm3 1 0>;
					default-state = "off";
				};
			};
			leddrv2_3: leddrv8 {
				compatible = "gpio-leds";
				uid {
					gpios = <&ubm3 4 0>;
					default-state = "off";
				};
			};
			leddrv1_4: leddrv9 {
				compatible = "gpio-leds";
				uid {
					gpios = <&ubm4 1 0>;
					default-state = "off";
				};
			};
			leddrv2_4: leddrv10 {
				compatible = "gpio-leds";
				uid {
					gpios = <&ubm4 4 0>;
					default-state = "off";
				};
			};
			leddrv1_5: leddrv11 {
				compatible = "gpio-leds";
				uid {
					gpios = <&ubm5 1 0>;
					default-state = "off";
				};
			};
			leddrv2_5: leddrv12 {
				compatible = "gpio-leds";
				uid {
					gpios = <&ubm5 4 0>;
					default-state = "off";
				};
			};
			leddrv1_6: leddrv13 {
				compatible = "gpio-leds";
				uid {
					gpios = <&ubm6 1 0>;
					default-state = "off";
				};
			};
			leddrv2_6: leddrv14 {
				compatible = "gpio-leds";
				uid {
					gpios = <&ubm6 4 0>;
					default-state = "off";
				};
			};
			leddrv1_7: leddrv15 {
				compatible = "gpio-leds";
				uid {
					gpios = <&ubm7 1 0>;
					default-state = "off";
				};
			};
			leddrv2_7: leddrv16 {
				compatible = "gpio-leds";
				uid {
					gpios = <&ubm7 4 0>;
					default-state = "off";
				};
			};
			leddrv1_8: leddrv17 {
				compatible = "gpio-leds";
				uid {
					gpios = <&ubm8 1 0>;
					default-state = "off";
				};
			};
			leddrv2_8: leddrv18 {
				compatible = "gpio-leds";
				uid {
					gpios = <&ubm8 4 0>;
					default-state = "off";
				};
			};
			leddrv1_9: leddrv19 {
				compatible = "gpio-leds";
				uid {
					gpios = <&ubm9 1 0>;
					default-state = "off";
				};
			};
			leddrv2_9: leddrv20 {
				compatible = "gpio-leds";
				uid {
					gpios = <&ubm9 4 0>;
					default-state = "off";
				};
			};
			leddrv1_10: leddrv21 {
				compatible = "gpio-leds";
				uid {
					gpios = <&ubm10 1 0>;
					default-state = "off";
				};
			};
			leddrv2_10: leddrv22 {
				compatible = "gpio-leds";
				uid {
					gpios = <&ubm10 4 0>;
					default-state = "off";
				};
			};
			leddrv1_11: leddrv23 {
				compatible = "gpio-leds";
				uid {
					gpios = <&ubm11 1 0>;
					default-state = "off";
				};
			};
			leddrv2_11: leddrv24 {
				compatible = "gpio-leds";
				uid {
					gpios = <&ubm11 4 0>;
					default-state = "off";
				};
			};
			leddrv1_12: leddrv25 {
				compatible = "gpio-leds";
				uid {
					gpios = <&ubm12 1 0>;
					default-state = "off";
				};
			};
			leddrv2_12: leddrv26 {
				compatible = "gpio-leds";
				uid {
					gpios = <&ubm12 4 0>;
					default-state = "off";
				};
			};
			leddrv1_13: leddrv27 {
				compatible = "gpio-leds";
				uid {
					gpios = <&ubm13 1 0>;
					default-state = "off";
				};
			};
			leddrv2_13: leddrv28 {
				compatible = "gpio-leds";
				uid {
					gpios = <&ubm13 4 0>;
					default-state = "off";
				};
			};
			leddrv1_14: leddrv29 {
				compatible = "gpio-leds";
				uid {
					gpios = <&ubm14 1 0>;
					default-state = "off";
				};
			};
			leddrv2_14: leddrv30 {
				compatible = "gpio-leds";
				uid {
					gpios = <&ubm14 4 0>;
					default-state = "off";
				};
			};
			leddrv1_15: leddrv31 {
				compatible = "gpio-leds";
				uid {
					gpios = <&ubm15 1 0>;
					default-state = "off";
				};
			};
			leddrv2_15: leddrv32 {
				compatible = "gpio-leds";
				uid {
					gpios = <&ubm15 4 0>;
					default-state = "off";
				};
			};
			leddrv1_16: leddrv33 {
				compatible = "gpio-leds";
				uid {
					gpios = <&ubm16 1 0>;
					default-state = "off";
				};
			};
			leddrv2_16: leddrv34 {
				compatible = "gpio-leds";
				uid {
					gpios = <&ubm16 4 0>;
					default-state = "off";
				};
			};
			leddrv1_17: leddrv35 {
				compatible = "gpio-leds";
				uid {
					gpios = <&ubm17 1 0>;
					default-state = "off";
				};
			};
			leddrv2_17: leddrv36 {
				compatible = "gpio-leds";
				uid {
					gpios = <&ubm17 4 0>;
					default-state = "off";
				};
			};
			leddrv1_18: leddrv37 {
				compatible = "gpio-leds";
				uid {
					gpios = <&ubm18 1 0>;
					default-state = "off";
				};
			};
			leddrv2_18: leddrv38 {
				compatible = "gpio-leds";
				uid {
					gpios = <&ubm18 4 0>;
					default-state = "off";
				};
			};
			leddrv1_19: leddrv39 {
				compatible = "gpio-leds";
				uid {
					gpios = <&ubm19 1 0>;
					default-state = "off";
				};
			};
			leddrv2_19: leddrv40 {
				compatible = "gpio-leds";
				uid {
					gpios = <&ubm19 4 0>;
					default-state = "off";
				};
			};
			leddrv1_20: leddrv41 {
				compatible = "gpio-leds";
				uid {
					gpios = <&ubm20 1 0>;
					default-state = "off";
				};
			};
			leddrv2_20: leddrv42 {
				compatible = "gpio-leds";
				uid {
					gpios = <&ubm20 4 0>;
					default-state = "off";
				};
			};
			leddrv1_21: leddrv43 {
				compatible = "gpio-leds";
				uid {
					gpios = <&ubm21 1 0>;
					default-state = "off";
				};
			};
			leddrv2_21: leddrv44 {
				compatible = "gpio-leds";
				uid {
					gpios = <&ubm21 4 0>;
					default-state = "off";
				};
			};
			leddrv1_22: leddrv45 {
				compatible = "gpio-leds";
				uid {
					gpios = <&ubm22 1 0>;
					default-state = "off";
				};
			};
			leddrv2_22: leddrv46 {
				compatible = "gpio-leds";
				uid {
					gpios = <&ubm22 4 0>;
					default-state = "off";
				};
			};
			leddrv1_23: leddrv47 {
				compatible = "gpio-leds";
				uid {
					gpios = <&ubm23 1 0>;
					default-state = "off";
				};
			};
			leddrv2_23: leddrv48 {
				compatible = "gpio-leds";
				uid {
					gpios = <&ubm23 4 0>;
					default-state = "off";
				};
			};
			leddrv1_24: leddrv49 {
				compatible = "gpio-leds";
				uid {
					gpios = <&ubm24 1 0>;
					default-state = "off";
				};
			};
			leddrv2_24: leddrv50 {
				compatible = "gpio-leds";
				uid {
					gpios = <&ubm24 4 0>;
					default-state = "off";
				};
			};
			leddrv1_25: leddrv51 {
				compatible = "gpio-leds";
				uid {
					gpios = <&ubm25 1 0>;
					default-state = "off";
				};
			};
			leddrv2_25: leddrv52 {
				compatible = "gpio-leds";
				uid {
					gpios = <&ubm25 4 0>;
					default-state = "off";
				};
			};
			leddrv1_26: leddrv53 {
				compatible = "gpio-leds";
				uid {
					gpios = <&ubm26 1 0>;
					default-state = "off";
				};
			};
			leddrv2_26: leddrv54 {
				compatible = "gpio-leds";
				uid {
					gpios = <&ubm26 4 0>;
					default-state = "off";
				};
			};
			leddrv1_27: leddrv55 {
				compatible = "gpio-leds";
				uid {
					gpios = <&ubm27 1 0>;
					default-state = "off";
				};
			};
			leddrv2_27: leddrv56 {
				compatible = "gpio-leds";
				uid {
					gpios = <&ubm27 4 0>;
					default-state = "off";
				};
			};

		}; /* __overlay__ */
	}; /* fragment@5 */

}; /* / */
